AUTOSAR XML (schema 4-2-1)
package /MICROSAR/BswM_swc
  mode declaration group MdgBswMRequestShutdown: initial-mode=BSWM_REQUESTSHUTDOWN_INACTIVE
    mode BSWM_REQUESTSHUTDOWN_INACTIVE
    mode BSWM_REQUESTSHUTDOWN_ACTIVE
  mode declaration group ESH_Mode: initial-mode=STARTUP
    5 x mode:
      STARTUP
      RUN
      POSTRUN
      WAKEUP
      SHUTDOWN
  data type mapping set BswMMappingSet  # Contains Mapping for ModeDeclarations Groups which are provided by BswM.
    mode-request-type-maps:
      implementation-data-type=BswM_MdgBswMRequestShutdown, mode-group=MdgBswMRequestShutdown
      implementation-data-type=BswM_ESH_Mode, mode-group=ESH_Mode
package /MICROSAR/BswM_swc/ComponentTypes
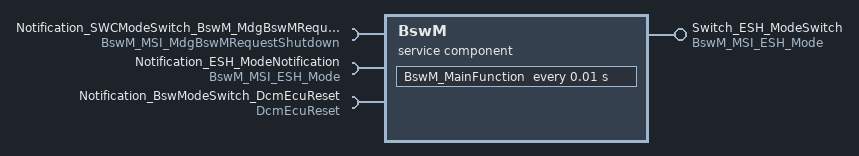
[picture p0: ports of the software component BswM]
  service sw component type BswM: category=SERVICE_COMPONENT
    provide port Switch_ESH_ModeSwitch: provided-interface=BswM_MSI_ESH_Mode
    require port Notification_SWCModeSwitch_BswM_MdgBswMRequestShutdown: required-interface=BswM_MSI_MdgBswMRequestShutdown
    require port Notification_ESH_ModeNotification: required-interface=BswM_MSI_ESH_Mode
    require port Notification_BswModeSwitch_DcmEcuReset: required-interface=DcmEcuReset
    behavior BswMInternalBehavior: handle-termination-and-restart=NO-SUPPORT, included-data-type-set=data-type=[BswM_MdgBswMRequestShutdown, BswM_ESH_Mode]
      timing event Timer_BswM_MainFunction: start-on-event=BswM_MainFunction, period=0.01
      port-api-options:
        enable-take-address=true, indirect-api=false, port=Switch_ESH_ModeSwitch
        enable-take-address=true, indirect-api=false, port=Notification_SWCModeSwitch_BswM_MdgBswMRequestShutdown
        enable-take-address=true, indirect-api=false, port=Notification_ESH_ModeNotification
        enable-take-address=true, indirect-api=false, port=Notification_BswModeSwitch_DcmEcuReset
      runnable BswM_MainFunction
        mode-access-points:
          Notification_SWCModeSwitch_BswM_MdgBswMRequestShutdown.BswM_MDGP_MdgBswMRequestShutdown
          Notification_ESH_ModeNotification.BswM_MDGP_ESH_Mode
          Notification_BswModeSwitch_DcmEcuReset.DcmEcuReset
        mode switch point ModeSwitchPointBswM_MainFunction_Switch_ESH_ModeSwitch_BswM_MDGP_ESH_Mode: mode-group=Switch_ESH_ModeSwitch.BswM_MDGP_ESH_Mode
  swc implementation BswMImplementation: programming-language=C, behavior=BswMInternalBehavior
package /MICROSAR/BswM_swc/DataTypes
  impl type BswM_MdgBswMRequestShutdown: compu {1=BSWM_REQUESTSHUTDOWN_INACTIVE, 0=BSWM_REQUESTSHUTDOWN_ACTIVE}, implementation-data-type=uint8  # Unique value for each user
  impl type BswM_ESH_Mode: compu {0=STARTUP, 1=RUN, 2=POSTRUN, 3=WAKEUP, 4=SHUTDOWN}, implementation-data-type=uint8  # Unique value for each user
package /MICROSAR/BswM_swc/Interfaces
  mode switch interface BswM_MSI_MdgBswMRequestShutdown: is-service=true, service-kind=BASIC-SOFTWARE-MODE-MANAGER
    mode group BswM_MDGP_MdgBswMRequestShutdown: type=MdgBswMRequestShutdown
  mode switch interface BswM_MSI_ESH_Mode: is-service=true, service-kind=BASIC-SOFTWARE-MODE-MANAGER
    mode group BswM_MDGP_ESH_Mode: type=ESH_Mode
